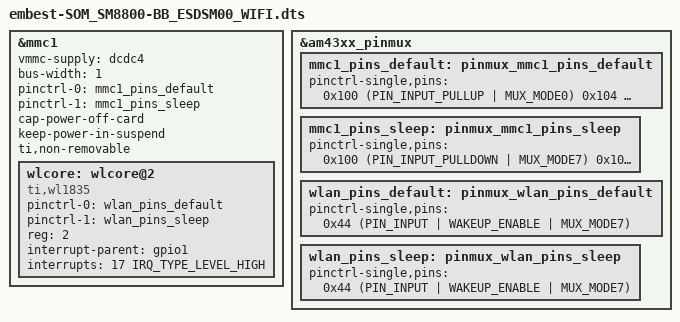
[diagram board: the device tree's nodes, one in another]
/*
 * Copyright (C) 2016 Embest Technology Co., Ltd., - http://www.embest-tech.com
 *
 * This program is free software; you can redistribute it and/or modify
 * it under the terms of the GNU General Public License version 2 as
 * published by the Free Software Foundation.
 *
 * This dts is for embest own product:
 * SOM-PH8800
 */
/*/dts-v1/;*/

#include "embest-SOM_SM8800-BB_ESDSM00.dts"

&mmc1 {
	status = "okay";
	vmmc-supply = <&dcdc4>;
	bus-width = <1>;
	pinctrl-names = "default", "sleep";
	pinctrl-0 = <&mmc1_pins_default>;
	pinctrl-1 = <&mmc1_pins_sleep>;
	cap-power-off-card;
	keep-power-in-suspend;
	ti,non-removable;

	#address-cells = <1>;
	#size-cells = <0>;
	wlcore: wlcore@2 {
		compatible = "ti,wl1835";
		pinctrl-names = "default", "sleep";
		pinctrl-0 = <&wlan_pins_default>;
		pinctrl-1 = <&wlan_pins_sleep>;
		reg = <2>;
		interrupt-parent = <&gpio1>;
		interrupts = <17 IRQ_TYPE_LEVEL_HIGH>;
	};
};

&am43xx_pinmux {
	mmc1_pins_default: pinmux_mmc1_pins_default {
		pinctrl-single,pins = <
			0x100 (PIN_INPUT_PULLUP | MUX_MODE0) /* (D1) mmc0_clk.mmc0_clk */
			0x104 (PIN_INPUT_PULLUP | MUX_MODE0) /* (D2) mmc0_cmd.mmc0_cmd */
			0xfc (PIN_INPUT_PULLUP | MUX_MODE0) /* (C1) mmc0_dat0.mmc0_dat0 */
			0xf8 (PIN_INPUT_PULLUP | MUX_MODE0) /* (C2) mmc0_dat1.mmc0_dat1 */
			0xf4 (PIN_INPUT_PULLUP | MUX_MODE0) /* (B2) mmc0_dat2.mmc0_dat2 */
			0xf0 (PIN_INPUT_PULLUP | MUX_MODE0) /* (B1) mmc0_dat3.mmc0_dat3 */
		>;
	};

	mmc1_pins_sleep: pinmux_mmc1_pins_sleep {
		pinctrl-single,pins = <
			0x100 (PIN_INPUT_PULLDOWN | MUX_MODE7) /* (D1) mmc0_clk.mmc0_clk */
			0x104 (PIN_INPUT_PULLDOWN | MUX_MODE7) /* (D2) mmc0_cmd.mmc0_cmd */
			0xfc (PIN_INPUT_PULLDOWN | MUX_MODE7) /* (C1) mmc0_dat0.mmc0_dat0 */
			0xf8 (PIN_INPUT_PULLDOWN | MUX_MODE7) /* (C2) mmc0_dat1.mmc0_dat1 */
			0xf4 (PIN_INPUT_PULLDOWN | MUX_MODE7) /* (B2) mmc0_dat2.mmc0_dat2 */
			0xf0 (PIN_INPUT_PULLDOWN | MUX_MODE7) /* (B1) mmc0_dat3.mmc0_dat3 */
		>;
	};

	wlan_pins_default: pinmux_wlan_pins_default {
		pinctrl-single,pins = <
			0x44 (PIN_INPUT | WAKEUP_ENABLE | MUX_MODE7)	/*  WL_IRQ gpmc_a1.gpio1_17*/
		>;
	};

	wlan_pins_sleep: pinmux_wlan_pins_sleep {
		pinctrl-single,pins = <
			0x44 (PIN_INPUT | WAKEUP_ENABLE | MUX_MODE7)	/*  WL_IRQ gpmc_a1.gpio1_17*/
		>;
	};
};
